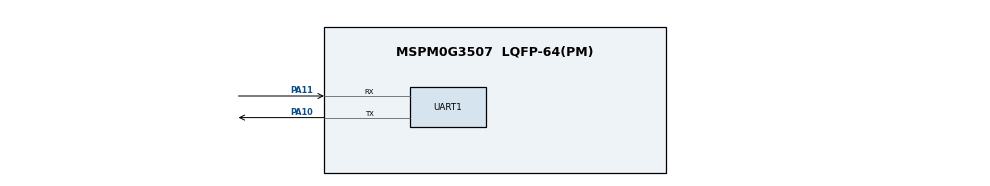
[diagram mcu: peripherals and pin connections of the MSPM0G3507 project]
/**
 * These arguments were used when this file was generated. They will be automatically applied on subsequent loads
 * via the GUI or CLI. Run CLI with '--help' for additional information on how to override these arguments.
 * @cliArgs --device "MSPM0G350X" --part "Default" --package "LQFP-64(PM)" --product "mspm0_sdk@2.11.00.07"
 * @v2CliArgs --device "MSPM0G3507" --package "LQFP-64(PM)" --product "mspm0_sdk@2.11.00.07"
 * @versions {"tool":"1.26.2+4477"}
 */

/**
 * Import the modules used in this configuration.
 */
const Board         = scripting.addModule("/ti/driverlib/Board");
const DAC12         = scripting.addModule("/ti/driverlib/DAC12");
const GPIO          = scripting.addModule("/ti/driverlib/GPIO", {}, false);
const GPIO1         = GPIO.addInstance();
const GPIO2         = GPIO.addInstance();
const SYSCTL        = scripting.addModule("/ti/driverlib/SYSCTL");
const TIMER         = scripting.addModule("/ti/driverlib/TIMER", {}, false);
const TIMER1        = TIMER.addInstance();
const TIMER2        = TIMER.addInstance();
const UART          = scripting.addModule("/ti/driverlib/UART", {}, false);
const UART1         = UART.addInstance();
const VREF          = scripting.addModule("/ti/driverlib/VREF");
const ProjectConfig = scripting.addModule("/ti/project_config/ProjectConfig");

/**
 * Write custom configuration values to the imported modules.
 */
const gate8  = system.clockTree["MFPCLKGATE"];
gate8.enable = true;



GPIO1.$name                               = "LED";
GPIO1.associatedPins.create(4);
GPIO1.associatedPins[0].$name             = "RED";
GPIO1.associatedPins[0].assignedPort      = "PORTB";
GPIO1.associatedPins[0].launchPadShortcut = "LED2RedEn";
GPIO1.associatedPins[1].launchPadShortcut = "LED2GreenEn";
GPIO1.associatedPins[1].$name             = "GREEN";
GPIO1.associatedPins[2].launchPadShortcut = "LED2BlueEn";
GPIO1.associatedPins[2].$name             = "BLUE";
GPIO1.associatedPins[3].$name             = "LED1";
GPIO1.associatedPins[3].launchPadShortcut = "LED1En";

GPIO2.$name                               = "KEY";
GPIO2.associatedPins[0].launchPadShortcut = "Button3En";
GPIO2.associatedPins[0].$name             = "S2";

SYSCTL.MFPCLKEn = true;

DAC12.dacOutputPinEn  = true;
DAC12.dacAmplifier    = "ON";
DAC12.dacPosVREF      = "VEREFP";
DAC12.dacNegVREF      = "VEREFN";
DAC12.dacFIFOEn       = true;
DAC12.dacFIFOTrigger  = "HWTRIG0";
DAC12.sub0ChanID      = 2;
DAC12.dacSampleTimerEn  = false;
DAC12.dacEnabledInterrupts = ["FIFO_TWO_QTRS_EMPTY"];

VREF.basicIntVolt   = "DL_VREF_BUFCONFIG_OUTPUT_2_5V";
VREF.checkVREFReady = true;

TIMER1.$name                       = "TIMER_0";
TIMER1.timerClkSrc                 = "LFCLK";
TIMER1.timerClkPrescale            = 8;
TIMER1.timerPeriod                 = "1000 ms";
TIMER1.timerMode                   = "PERIODIC";
TIMER1.interrupts                  = ["ZERO"];
TIMER1.event1PublisherChannel      = 1;
TIMER1.event1ControllerInterruptEn = ["ZERO_EVENT"];
TIMER1.peripheral.$assign          = "TIMG0";

TIMER2.$name                       = "TIMER_1";
TIMER2.timerClkSrc                 = "BUSCLK";
TIMER2.timerClkPrescale            = 1;
TIMER2.timerPeriod                 = "1 us";
TIMER2.timerMode                   = "PERIODIC";
TIMER2.event1PublisherChannel      = 2;
TIMER2.event1ControllerInterruptEn = ["ZERO_EVENT"];
TIMER2.peripheral.$assign          = "TIMG6";

UART1.$name                    = "UART_0";
UART1.uartClkSrc               = "LFCLK";
UART1.ovsRate                  = "3";
UART1.enabledInterrupts        = ["RX"];
UART1.peripheral.$assign       = "UART0";
UART1.peripheral.rxPin.$assign = "PA11";
UART1.peripheral.txPin.$assign = "PA10";
UART1.txPinConfig.$name        = "ti_driverlib_gpio_GPIOPinGeneric0";
UART1.rxPinConfig.$name        = "ti_driverlib_gpio_GPIOPinGeneric1";

VREF.vrefPosPinConfig.$name = "ti_driverlib_gpio_GPIOPinGeneric2";

ProjectConfig.genLibCMSIS = true;

/**
 * Pinmux solution for unlocked pins/peripherals. This ensures that minor changes to the automatic solver in a future
 * version of the tool will not impact the pinmux you originally saw.  These lines can be completely deleted in order to
 * re-solve from scratch.
 */
Board.peripheral.$suggestSolution            = "DEBUGSS";
Board.peripheral.swclkPin.$suggestSolution   = "PA20";
Board.peripheral.swdioPin.$suggestSolution   = "PA19";
GPIO1.associatedPins[0].pin.$suggestSolution = "PB26";
GPIO1.associatedPins[1].pin.$suggestSolution = "PB27";
GPIO1.associatedPins[2].pin.$suggestSolution = "PB22";
GPIO1.associatedPins[3].pin.$suggestSolution = "PA0";
GPIO2.associatedPins[0].pin.$suggestSolution = "PB21";
SYSCTL.peripheral.$suggestSolution           = "SYSCTL";
